AUTOSAR XML (schema 314)
package /ComponentType
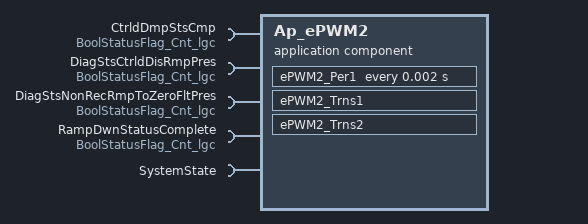
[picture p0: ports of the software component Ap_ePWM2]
  application software component type Ap_ePWM2
    5 x require port:
      CtrldDmpStsCmp: unqueued-receiver-com-spec{data-element=Cnt_lgc, init-value=D_FALSE_CNT_LGC}, required-interface=BoolStatusFlag_Cnt_lgc
      DiagStsCtrldDisRmpPres: unqueued-receiver-com-spec{data-element=Cnt_lgc, init-value=D_FALSE_CNT_LGC}, required-interface=BoolStatusFlag_Cnt_lgc
      DiagStsNonRecRmpToZeroFltPres: unqueued-receiver-com-spec{data-element=Cnt_lgc, init-value=D_FALSE_CNT_LGC}, required-interface=BoolStatusFlag_Cnt_lgc
      RampDwnStatusComplete: unqueued-receiver-com-spec{data-element=Cnt_lgc, init-value=D_FALSE_CNT_LGC}, required-interface=BoolStatusFlag_Cnt_lgc
      SystemState: required-interface=SystemState
  internal behavior Ap_ePWM2_InternalBehavior: component=Ap_ePWM2
    timing event TMT_ePWM2_Per1: start-on-event=ePWM2_Per1, period=0.002
    mode switch event MST_ePWM2_Trns1_0: start-on-event=ePWM2_Trns1, activation=ENTRY, mode=SystemState.Mode.OPERATE
    mode switch event MST_ePWM2_Trns2_0: start-on-event=ePWM2_Trns2, activation=EXIT, mode=SystemState.Mode.OPERATE
    port-api-options:
      enable-take-address=false, indirect-api=false, port=CtrldDmpStsCmp
      enable-take-address=false, indirect-api=false, port=DiagStsCtrldDisRmpPres
      enable-take-address=false, indirect-api=false, port=DiagStsNonRecRmpToZeroFltPres
      enable-take-address=false, indirect-api=false, port=RampDwnStatusComplete
      enable-take-address=false, indirect-api=false, port=SystemState
    runnable ePWM2_Per1
      4 x data read access:
        READ_CtrldDmpStsCmp_Cnt_lgc: data-element=CtrldDmpStsCmp.Cnt_lgc
        READ_DiagStsCtrldDisRmpPres_Cnt_lgc: data-element=DiagStsCtrldDisRmpPres.Cnt_lgc
        READ_DiagStsNonRecRmpToZeroFltPres_Cnt_lgc: data-element=DiagStsNonRecRmpToZeroFltPres.Cnt_lgc
        READ_RampDwnStatusComplete_Cnt_lgc: data-element=RampDwnStatusComplete.Cnt_lgc
    runnable ePWM2_Trns1
    runnable ePWM2_Trns2
  swc implementation Ap_ePWM2_Implementation: behavior=Ap_ePWM2_InternalBehavior
    code-descriptors:
      code Code: type=SRC
